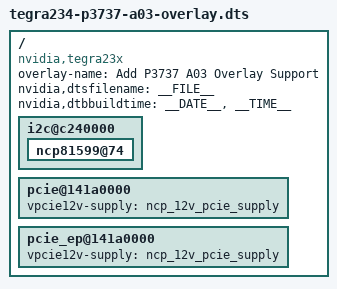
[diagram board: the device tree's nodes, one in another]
/*
 * Copyright (c) 2022, NVIDIA CORPORATION.  All rights reserved.
 *
 * This program is free software; you can redistribute it and/or modify
 * it under the terms of the GNU General Public License as published by
 * the Free Software Foundation; version 2 of the License.
 *
 * This program is distributed in the hope that it will be useful, but WITHOUT
 * ANY WARRANTY; without even the implied warranty of MERCHANTABILITY or
 * FITNESS FOR A PARTICULAR PURPOSE.  See the GNU General Public License for
 * more details.
 */

/dts-v1/;
/plugin/;

/ {
	overlay-name = "Add P3737 A03 Overlay Support";
	compatible = "nvidia,tegra23x";
	nvidia,dtsfilename = __FILE__;
	nvidia,dtbbuildtime = __DATE__, __TIME__;

	/* PCIe 12V supply through NCP for TS3 */
	fragment@0 {
		target-path = "/";
		board_config {
			ids = "3737-0000-TS3","3737-0000-200","3737-0000-300";
		};
		 __overlay__ {
			i2c@c240000 {
				ncp81599@74 {
					status = "okay";
				};
			};
			pcie@141a0000 {
				vpcie12v-supply = <&ncp_12v_pcie_supply>;
			};
			pcie_ep@141a0000 {
				vpcie12v-supply = <&ncp_12v_pcie_supply>;
			};
		};
	};
};
